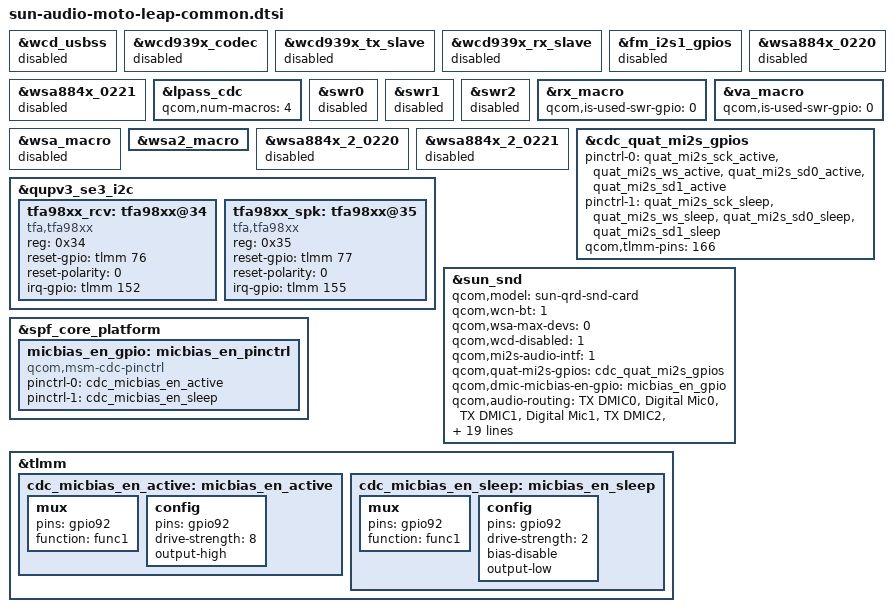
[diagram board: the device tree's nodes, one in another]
// SPDX-License-Identifier: BSD-3-Clause
/*
 * Copyright (c) 2023 Qualcomm Innovation Center, Inc. All rights reserved.
 */

#include "sun-audio-overlay.dtsi"

&wcd_usbss {
	status = "disabled";
};

&wcd939x_codec {
	status = "disabled";
};

&wcd939x_tx_slave {
	status = "disabled";
};

&wcd939x_rx_slave {
	status = "disabled";
};

&fm_i2s1_gpios {
	status = "disabled";
};

&wsa884x_0220 {
	status = "disabled";
};

&wsa884x_0221 {
	status = "disabled";
};

&lpass_cdc {
	qcom,num-macros = <4>;
};

&swr0 {
	status = "disabled";
};

&swr1 {
	status = "disabled";
};

&swr2 {
	status = "disabled";
};

&rx_macro {
	qcom,is-used-swr-gpio = <0>;
};

&va_macro {
	qcom,is-used-swr-gpio = <0>;
};

&wsa_macro {
	status = "disabled";
};

&wsa2_macro {
    /delete-property/ #cooling-cells;
};

&wsa884x_2_0220 {
	status = "disabled";
};

&wsa884x_2_0221 {
	status = "disabled";
};

&qupv3_se3_i2c {
	#address-cells = <1>;
	#size-cells = <0>;
	status = "okay";
	tfa98xx_rcv: tfa98xx@34 { /* SPKL */
		compatible = "tfa,tfa98xx";
		reg = <0x34>;
		reset-gpio = <&tlmm 76 0>;
		reset-polarity = <0>;
		irq-gpio = <&tlmm 152 0>;
		status = "okay";
	};
	tfa98xx_spk: tfa98xx@35 { /* SPKR */
		compatible = "tfa,tfa98xx";
		reg = <0x35>;
		reset-gpio = <&tlmm 77 0>;
		reset-polarity = <0>;
		irq-gpio = <&tlmm 155 0>;
		status = "okay";
	};
};

&cdc_quat_mi2s_gpios {
	status = "okay";
	pinctrl-0 = <&quat_mi2s_sck_active &quat_mi2s_ws_active
			&quat_mi2s_sd0_active &quat_mi2s_sd1_active>;
	pinctrl-1 = <&quat_mi2s_sck_sleep &quat_mi2s_ws_sleep
			&quat_mi2s_sd0_sleep &quat_mi2s_sd1_sleep>;
	qcom,tlmm-pins = <166>;
};

&sun_snd {
	qcom,model = "sun-qrd-snd-card";
	qcom,wcn-bt = <1>;
	qcom,wsa-max-devs = <0>;
	qcom,wcd-disabled = <1>;
	qcom,mi2s-audio-intf = <1>;
	qcom,quat-mi2s-gpios = <&cdc_quat_mi2s_gpios>;
	qcom,dmic-micbias-en-gpio = <&micbias_en_gpio>;
	qcom,audio-routing =
		"TX DMIC0", "Digital Mic0",
		"TX DMIC1", "Digital Mic1",
		"TX DMIC2", "Digital Mic2",
		"TX DMIC3", "Digital Mic3",
		"TX DMIC4", "Digital Mic4",
		"TX DMIC5", "Digital Mic5",
		"TX DMIC6", "Digital Mic6",
		"TX DMIC7", "Digital Mic7",
		"HAP_IN", "WSA2_HAPT OUT",
		"RX_TX DEC0_INP", "TX DEC0 MUX",
		"RX_TX DEC1_INP", "TX DEC1 MUX",
		"RX_TX DEC2_INP", "TX DEC2 MUX",
		"RX_TX DEC3_INP", "TX DEC3 MUX",
		"VA SWR_INPUT", "VA_SWR_CLK",
		"VA_AIF1 CAP", "VA_SWR_CLK",
		"VA_AIF2 CAP", "VA_SWR_CLK",
		"VA_AIF3 CAP", "VA_SWR_CLK",
		"VA DMIC0", "Digital Mic0",
		"VA DMIC1", "Digital Mic1",
		"VA DMIC2", "Digital Mic2",
		"VA DMIC3", "Digital Mic3",
		"VA DMIC4", "Digital Mic4",
		"VA DMIC5", "Digital Mic5",
		"VA DMIC6", "Digital Mic6",
		"VA DMIC7", "Digital Mic7";
	asoc-codec  = <&stub_codec>, <&lpass_cdc>, <&swr_haptics>,
			<&tfa98xx_rcv>, <&tfa98xx_spk>;
	asoc-codec-names = "msm-stub-codec.1", "lpass-cdc", "swr-haptics",
			"tfa98xx-0034", "tfa98xx-0035";
};

&spf_core_platform  {
	micbias_en_gpio: micbias_en_pinctrl {
		compatible = "qcom,msm-cdc-pinctrl";
		pinctrl-names = "aud_active", "aud_sleep";
		pinctrl-0 = <&cdc_micbias_en_active>;
		pinctrl-1 = <&cdc_micbias_en_sleep>;
		#gpio-cells = <0>;
	};
};

&tlmm {
	cdc_micbias_en_active: micbias_en_active {
		mux {
			pins = "gpio92";
			function = "func1";
		};

		config {
			pins = "gpio92";
			drive-strength = <8>;
			output-high;
		};
	};

	cdc_micbias_en_sleep: micbias_en_sleep {
		mux {
			pins = "gpio92";
			function = "func1";
		};

		config {
			pins = "gpio92";
			drive-strength = <2>;
			bias-disable;
			output-low;
		};
	};
};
